VERSION ""

NS_ :

BS_:

BU_:
VAL_TABLE_ mail_box_status_table 2 "Mailbox Enable RX Mode" 1 "Mailbox Enable TX Mode" 0 "Mailbox Disabled" ;
VAL_TABLE_ avr_type_mcu 1 "AVR_UART" 0 "AVR_I2C" ;

BO_ 3221225472 VECTOR__INDEPENDENT_SIG_MSG: 0 Vector__XXX
 SG_ avr_type : 0|1@1+ (1,0) [0|1] "" Vector__XXX

BO_ 9 avr_mcu_i2c: 8 Vector__XXX
 SG_ Mail_box_08 : 48|2@1+ (1,0) [0|0] "" Vector__XXX
 SG_ Mail_box_07 : 46|2@1+ (1,0) [0|0] "" Vector__XXX
 SG_ Mail_box_06 : 44|2@1+ (1,0) [0|0] "" Vector__XXX
 SG_ Mail_box_05 : 42|2@1+ (1,0) [0|0] "" Vector__XXX
 SG_ Mail_box_04 : 40|2@1+ (1,0) [0|0] "" Vector__XXX
 SG_ Mail_box_03 : 38|2@1+ (1,0) [0|0] "" Vector__XXX
 SG_ Mail_box_02 : 36|2@1+ (1,0) [0|0] "" Vector__XXX
 SG_ Mail_box_01 : 34|2@1+ (1,0) [0|0] "" Vector__XXX
 SG_ Mail_box_00 : 32|2@1+ (1,0) [0|0] "" Vector__XXX
 SG_ usart_framming_error : 28|1@1+ (1,0) [0|0] "" Vector__XXX
 SG_ usart_overrun : 27|1@1+ (1,0) [0|0] "" Vector__XXX
 SG_ usart_udr : 29|1@1+ (1,0) [0|0] "" Vector__XXX
 SG_ usart_2X : 25|1@1+ (1,0) [0|0] "" Vector__XXX
 SG_ usart_tx_complete : 30|1@1+ (1,0) [0|0] "" Vector__XXX
 SG_ usart_rx_complete : 31|1@1+ (1,0) [0|0] "" Vector__XXX
 SG_ usart_parity_error : 26|1@1+ (1,0) [0|0] "" Vector__XXX
 SG_ Error_Pasive : 16|1@1+ (1,0) [0|0] "" Vector__XXX
 SG_ bus_off_mode : 17|1@1- (1,0) [0|0] "" Vector__XXX
 SG_ enable_flag : 18|1@1+ (1,0) [0|0] "" Vector__XXX
 SG_ rx_bussy : 19|1@1+ (1,0) [0|0] "" Vector__XXX
 SG_ tx_bussy : 20|1@1+ (1,0) [0|0] "" Vector__XXX
 SG_ Overload_Frame : 22|1@1+ (1,0) [0|0] "" Vector__XXX
 SG_ tx_error : 8|8@1+ (1,0) [0|255] "" Vector__XXX
 SG_ rx_error : 0|8@1+ (1,0) [0|255] "" Vector__XXX

BO_ 16 avr_mcu_serial: 8 Vector__XXX
 SG_ Mail_box_08 : 48|2@1+ (1,0) [0|0] "" Vector__XXX
 SG_ Mail_box_07 : 46|2@1+ (1,0) [0|0] "" Vector__XXX
 SG_ Mail_box_06 : 44|2@1+ (1,0) [0|0] "" Vector__XXX
 SG_ Mail_box_05 : 42|2@1+ (1,0) [0|0] "" Vector__XXX
 SG_ Mail_box_04 : 40|2@1+ (1,0) [0|0] "" Vector__XXX
 SG_ Mail_box_03 : 38|2@1+ (1,0) [0|0] "" Vector__XXX
 SG_ Mail_box_02 : 36|2@1+ (1,0) [0|0] "" Vector__XXX
 SG_ Mail_box_01 : 34|2@1+ (1,0) [0|0] "" Vector__XXX
 SG_ Mail_box_00 : 32|2@1+ (1,0) [0|0] "" Vector__XXX
 SG_ usart_framming_error : 28|1@1+ (1,0) [0|0] "" Vector__XXX
 SG_ usart_overrun : 27|1@1+ (1,0) [0|0] "" Vector__XXX
 SG_ usart_udr : 29|1@1+ (1,0) [0|0] "" Vector__XXX
 SG_ usart_2X : 25|1@1+ (1,0) [0|0] "" Vector__XXX
 SG_ usart_tx_complete : 30|1@1+ (1,0) [0|0] "" Vector__XXX
 SG_ usart_rx_complete : 31|1@1+ (1,0) [0|0] "" Vector__XXX
 SG_ usart_parity_error : 26|1@1+ (1,0) [0|0] "" Vector__XXX
 SG_ Error_Pasive : 16|1@1+ (1,0) [0|0] "" Vector__XXX
 SG_ bus_off_mode : 17|1@1- (1,0) [0|0] "" Vector__XXX
 SG_ enable_flag : 18|1@1+ (1,0) [0|0] "" Vector__XXX
 SG_ rx_bussy : 19|1@1+ (1,0) [0|0] "" Vector__XXX
 SG_ tx_bussy : 20|1@1+ (1,0) [0|0] "" Vector__XXX
 SG_ Overload_Frame : 22|1@1+ (1,0) [0|0] "" Vector__XXX
 SG_ tx_error : 8|8@1+ (1,0) [0|255] "" Vector__XXX
 SG_ rx_error : 0|8@1+ (1,0) [0|255] "" Vector__XXX

BO_ 304 ECU_03: 8 Vector__XXX

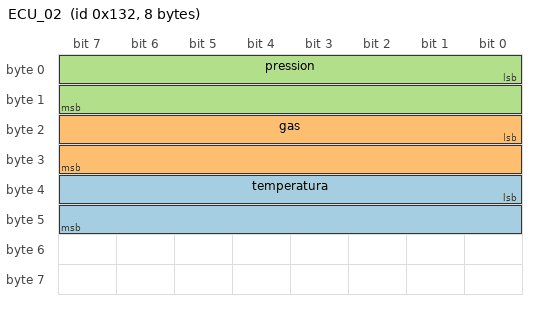
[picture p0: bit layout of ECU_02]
BO_ 306 ECU_02: 8 Vector__XXX
 SG_ temperatura : 32|16@1+ (1,0) [0|1000] "" Vector__XXX
 SG_ gas : 16|16@1+ (1,0) [0|1000] "" Vector__XXX
 SG_ pression : 0|16@1+ (1,0) [0|1000] "" Vector__XXX

BO_ 288 ECU_01: 8 Vector__XXX
 SG_ rpms : 0|16@1+ (1,0) [0|10000] "" Vector__XXX

BO_ 352 ECU_00: 8 Vector__XXX
 SG_ wheel_speed : 0|16@1+ (1,0) [0|2000] "" Vector__XXX

CM_ BO_ 3221225472 "This is a message for not used signals, created by Vector CANdb++ DBC OLE DB Provider.";
BA_DEF_  "BusType" STRING ;
BA_DEF_DEF_  "BusType" "CAN";
VAL_ 9 Mail_box_08 2 "Mailbox Enable RX Mode" 1 "Mailbox Enable TX Mode" 0 "Mailbox Disabled" ;
VAL_ 9 Mail_box_07 2 "Mailbox Enable RX Mode" 1 "Mailbox Enable TX Mode" 0 "Mailbox Disabled" ;
VAL_ 9 Mail_box_06 2 "Mailbox Enable RX Mode" 1 "Mailbox Enable TX Mode" 0 "Mailbox Disabled" ;
VAL_ 9 Mail_box_05 2 "Mailbox Enable RX Mode" 1 "Mailbox Enable TX Mode" 0 "Mailbox Disabled" ;
VAL_ 9 Mail_box_04 2 "Mailbox Enable RX Mode" 1 "Mailbox Enable TX Mode" 0 "Mailbox Disabled" ;
VAL_ 9 Mail_box_03 2 "Mailbox Enable RX Mode" 1 "Mailbox Enable TX Mode" 0 "Mailbox Disabled" ;
VAL_ 9 Mail_box_02 2 "Mailbox Enable RX Mode" 1 "Mailbox Enable TX Mode" 0 "Mailbox Disabled" ;
VAL_ 9 Mail_box_01 2 "Mailbox Enable RX Mode" 1 "Mailbox Enable TX Mode" 0 "Mailbox Disabled" ;
VAL_ 9 Mail_box_00 2 "Mailbox Enable RX Mode" 1 "Mailbox Enable TX Mode" 0 "Mailbox Disabled" ;
VAL_ 16 Mail_box_08 2 "Mailbox Enable RX Mode" 1 "Mailbox Enable TX Mode" 0 "Mailbox Disabled" ;
VAL_ 16 Mail_box_07 2 "Mailbox Enable RX Mode" 1 "Mailbox Enable TX Mode" 0 "Mailbox Disabled" ;
VAL_ 16 Mail_box_06 2 "Mailbox Enable RX Mode" 1 "Mailbox Enable TX Mode" 0 "Mailbox Disabled" ;
VAL_ 16 Mail_box_05 2 "Mailbox Enable RX Mode" 1 "Mailbox Enable TX Mode" 0 "Mailbox Disabled" ;
VAL_ 16 Mail_box_04 2 "Mailbox Enable RX Mode" 1 "Mailbox Enable TX Mode" 0 "Mailbox Disabled" ;
VAL_ 16 Mail_box_03 2 "Mailbox Enable RX Mode" 1 "Mailbox Enable TX Mode" 0 "Mailbox Disabled" ;
VAL_ 16 Mail_box_02 2 "Mailbox Enable RX Mode" 1 "Mailbox Enable TX Mode" 0 "Mailbox Disabled" ;
VAL_ 16 Mail_box_01 2 "Mailbox Enable RX Mode" 1 "Mailbox Enable TX Mode" 0 "Mailbox Disabled" ;
VAL_ 16 Mail_box_00 2 "Mailbox Enable RX Mode" 1 "Mailbox Enable TX Mode" 0 "Mailbox Disabled" ;
